# GICSS_GICSS_GIC_01800000h register map
Vendor: Texas Instruments
Peripheral module from a debugger description file (folder am62L).
Registers are 32-bit, access not given, no defined reset value unless marked. A register's access mark holds for its fields unless they carry their own. Offsets are as the file gives them; lines under a group give offsets from that group; [hi:lo] are bit positions; {n}, {i} and the like mark numbered series; 'fields as' and 'values as' point back to an identical list; <NAME> marks a mode.

## GICSS_GIC
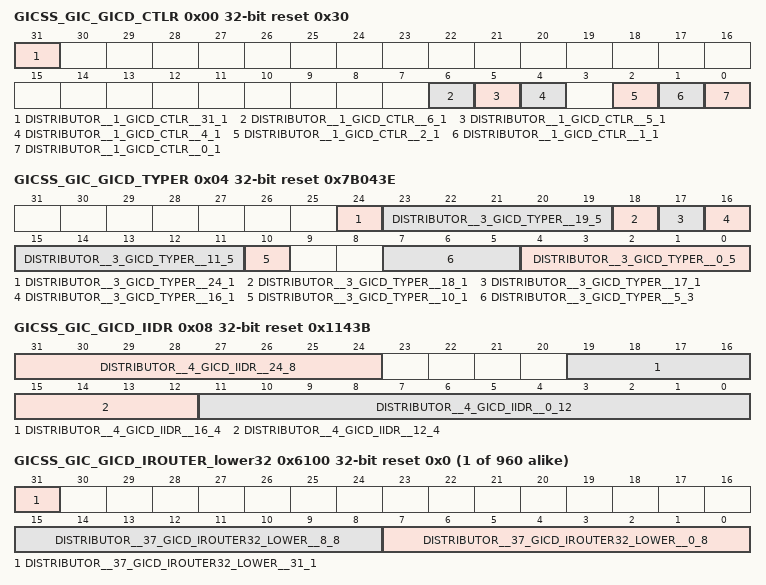
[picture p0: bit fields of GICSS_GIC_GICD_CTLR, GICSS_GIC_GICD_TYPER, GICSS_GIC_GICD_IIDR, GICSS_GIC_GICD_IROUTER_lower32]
0x00 GICSS_GIC_GICD_CTLR rw reset 0x30 — GICD_CTLR
  [31] DISTRIBUTOR__1_GICD_CTLR__31_1 — Register Write Pending
  [6] DISTRIBUTOR__1_GICD_CTLR__6_1 — S: DS
  [5] DISTRIBUTOR__1_GICD_CTLR__5_1 — S: ARE_NS
  [4] DISTRIBUTOR__1_GICD_CTLR__4_1 — NS: ARE_NS S: ARE_S
  [2] DISTRIBUTOR__1_GICD_CTLR__2_1 — S: EnableGrp1_S
  [1] DISTRIBUTOR__1_GICD_CTLR__1_1 — NS: EnableGrp1A S: EnableGrp1_NS
  [0] DISTRIBUTOR__1_GICD_CTLR__0_1 — NS: EnableGrp1 S: EnableGrp0
0x04 GICSS_GIC_GICD_TYPER ro reset 0x7B043E — GICD_TYPER
  [24] DISTRIBUTOR__3_GICD_TYPER__24_1 — A3V
  [23:19] DISTRIBUTOR__3_GICD_TYPER__19_5 — IDbits
  [18] DISTRIBUTOR__3_GICD_TYPER__18_1 — DVIS
  [17] DISTRIBUTOR__3_GICD_TYPER__17_1 — LPIS
  [16] DISTRIBUTOR__3_GICD_TYPER__16_1 — MBIS
  [15:11] DISTRIBUTOR__3_GICD_TYPER__11_5 — LSPI
  [10] DISTRIBUTOR__3_GICD_TYPER__10_1 — SecurityExtn
  [7:5] DISTRIBUTOR__3_GICD_TYPER__5_3 — CPUNumber
  [4:0] DISTRIBUTOR__3_GICD_TYPER__0_5 — ITLinesNumber
0x08 GICSS_GIC_GICD_IIDR ro reset 0x1143B — GICD_IIDR
  [31:24] DISTRIBUTOR__4_GICD_IIDR__24_8 — ProductID
  [19:16] DISTRIBUTOR__4_GICD_IIDR__16_4 — Variant
  [15:12] DISTRIBUTOR__4_GICD_IIDR__12_4 — Revision
  [11:0] DISTRIBUTOR__4_GICD_IIDR__0_12 — Implementer
0x40 GICSS_GIC_GICD_SETSPI_NSR wo reset 0x0 — GICD_SETSPI_NSR
  [9:0] DISTRIBUTOR__5_GICD_SETSPI_NSR__0_10 — SPI ID
0x48 GICSS_GIC_GICD_CLRSPI_NSR wo reset 0x0 — GICD_CLRSPI_NSR
  [9:0] DISTRIBUTOR__6_GICD_CLRSPI_NSR__0_10 — SPI ID
0x50 GICSS_GIC_GICD_SETSPI_SR wo reset 0x0 — GICD_SETSPI_SR
  [9:0] DISTRIBUTOR__7_GICD_SETSPI_SR__0_10 — SPI ID
0x58 GICSS_GIC_GICD_CLRSPI_SR wo reset 0x0 — GICD_CLRSPI_SR
  [9:0] DISTRIBUTOR__8_GICD_CLRSPI_SR__0_10 — SPI ID
0x80 GICSS_GIC_GICD_IGROUPR_SGI_PPI — GICD_IGROUPR0
{0x80+4i} GICSS_GIC_GICD_IGROUPR_SPI{i} (i=1..30) — GICD_IGROUPR{i}
{0x100+4i} GICSS_GIC_GICD_ISENABLER_SPI{i} (i=1..30) — GICD_ISENABLER{i}
{0x180+4i} GICSS_GIC_GICD_ICENABLER_SPI{i} (i=1..30) — GICD_ICENABLER{i}
{0x200+4i} GICSS_GIC_GICD_ISPENDR_SPI{i} (i=1..30) — GICD_ISPENDR{i}
{0x280+4i} GICSS_GIC_GICD_ICPENDR_SPI{i} (i=1..30) — GICD_ICPENDR{i}
{0x300+4i} GICSS_GIC_GICD_ISACTIVER_SPI{i} (i=1..30) — GICD_ISACTIVER{i}
{0x380+4i} GICSS_GIC_GICD_ICACTIVER_SPI{i} (i=1..30) — GICD_ICACTIVER{i}
{0x400+4i} GICSS_GIC_GICD_IPRIORITYR_SPI{i} (i=8..247) — GICD_IPRIORITYR{i}
{0x800+4i} GICSS_GIC_GICD_ITARGETSR_SPI{i} (i=8..247) — GICD_ITARGETSR{i}
{0xC00+4i} GICSS_GIC_GICD_ICFGR_SPI{i} (i=2..61) — GICD_ICFGR{i}
0xD00 GICSS_GIC_GICD_IGRPMODR_SGI_PPI — GICD_IGRPMODR0
{0xD00+4i} GICSS_GIC_GICD_IGRPMODR_SPI{i} (i=1..30) — GICD_IGRPMODR{i}
{0xE00+4i} GICSS_GIC_GICD_NSACR{i} (i=0..61) — GICD_NSACR{i}
{0x6000+8i} GICSS_GIC_GICD_IROUTER_lower{i} rw reset 0x0 (i=32..991) — GICD_IROUTER{i}_lower
  [31] DISTRIBUTOR__37_GICD_IROUTER{i}_LOWER__31_1 — IRM
  [15:8] DISTRIBUTOR__37_GICD_IROUTER{i}_LOWER__8_8 — A1
  [7:0] DISTRIBUTOR__37_GICD_IROUTER{i}_LOWER__0_8 — A0
{0x6004+8i} GICSS_GIC_GICD_IROUTER_upper{i} (i=32..991) — GICD_IROUTER{i}_upper
0xC000 GICSS_GIC_GICD_ESTATUSR ro reset 0x0 — GICD_ESTATUSR
  [31] DISTRIBUTOR__38_GICD_ESTATUSR__31_1 — SWRP
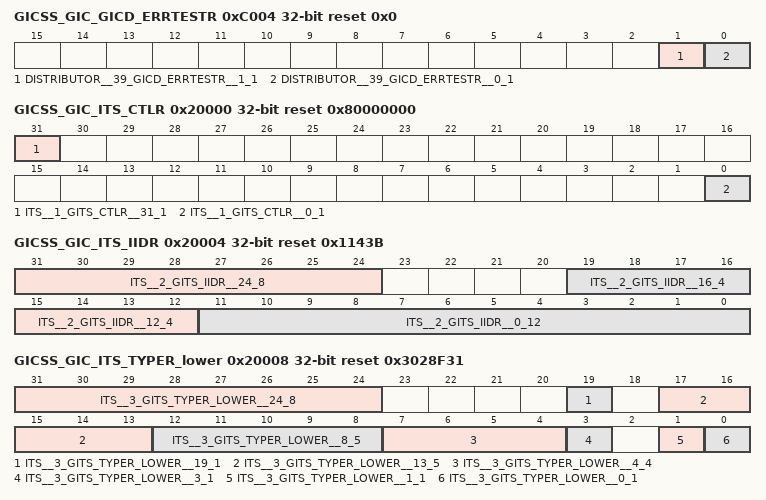
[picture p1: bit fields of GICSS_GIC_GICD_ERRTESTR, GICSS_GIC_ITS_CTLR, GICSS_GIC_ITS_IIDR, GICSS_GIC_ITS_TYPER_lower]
0xC004 GICSS_GIC_GICD_ERRTESTR wo reset 0x0 — GICD_ERRTESTR
  [1] DISTRIBUTOR__39_GICD_ERRTESTR__1_1 — AXIM_err
  [0] DISTRIBUTOR__39_GICD_ERRTESTR__0_1 — ECC_fatal
{0xC084+4i} GICSS_GIC_GICD_SPISR{i} (i=0..29) — GICD_SPISR{i}
{0xFFC0+4i} GICSS_GIC_GICD_PIDR{i} (i=4..7) — GICD_PIDR{i}
{0xFFE0+4i} GICSS_GIC_GICD_PIDR{i} (i=0..3) — GICD_PIDR{i}
{0xFFF0+4i} GICSS_GIC_GICD_CIDR{i} (i=0..3) — GICD_CIDR{i}
0x10040 GICSS_GIC_MSG_SETSPI_NSR wo reset 0x0 — GICD_SETSPI_NSR
  [9:0] MESSAGE_BASED_SPIS__1_GICD_SETSPI_NSR__0_10 — SPI ID
0x10048 GICSS_GIC_MSG_CLRSPI_NSR wo reset 0x0 — GICD_CLRSPI_NSR
  [9:0] MESSAGE_BASED_SPIS__2_GICD_CLRSPI_NSR__0_10 — SPI ID
0x10050 GICSS_GIC_MSG_SETSPI_SR wo reset 0x0 — GICD_SETSPI_SR
  [9:0] MESSAGE_BASED_SPIS__3_GICD_SETSPI_SR__0_10 — SPI ID
0x10058 GICSS_GIC_MSG_CLRSPI_SR wo reset 0x0 — GICD_CLRSPI_SR
  [9:0] MESSAGE_BASED_SPIS__4_GICD_CLRSPI_SR__0_10 — SPI ID
0x20000 GICSS_GIC_ITS_CTLR rw reset 0x80000000 — GITS_CTLR
  [31] ITS__1_GITS_CTLR__31_1 — Quiescent
  [0] ITS__1_GITS_CTLR__0_1 — Enabled
0x20004 GICSS_GIC_ITS_IIDR ro reset 0x1143B — GITS_IIDR
  [31:24] ITS__2_GITS_IIDR__24_8 — ProductID
  [19:16] ITS__2_GITS_IIDR__16_4 — Variant
  [15:12] ITS__2_GITS_IIDR__12_4 — Revision
  [11:0] ITS__2_GITS_IIDR__0_12 — Implementer
0x20008 GICSS_GIC_ITS_TYPER_lower ro reset 0x3028F31 — GITS_TYPER_lower
  [31:24] ITS__3_GITS_TYPER_LOWER__24_8 — HCC
  [19] ITS__3_GITS_TYPER_LOWER__19_1 — PTA
  [17:13] ITS__3_GITS_TYPER_LOWER__13_5 — Devbits
  [12:8] ITS__3_GITS_TYPER_LOWER__8_5 — IDbits
  [7:4] ITS__3_GITS_TYPER_LOWER__4_4 — ITT Entry Size
  [3] ITS__3_GITS_TYPER_LOWER__3_1 — Distributed
  [1] ITS__3_GITS_TYPER_LOWER__1_1 — VLPIS
  [0] ITS__3_GITS_TYPER_LOWER__0_1 — PLPIS
0x2000C GICSS_GIC_ITS_TYPER_upper — GITS_TYPER_upper
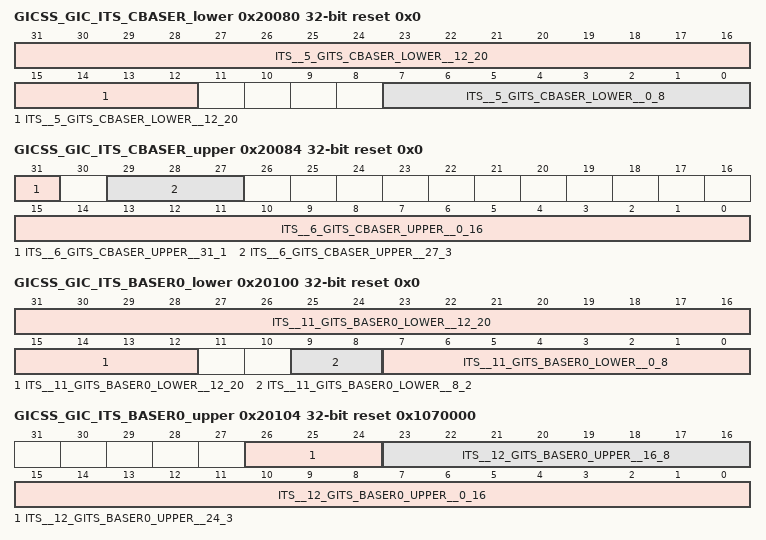
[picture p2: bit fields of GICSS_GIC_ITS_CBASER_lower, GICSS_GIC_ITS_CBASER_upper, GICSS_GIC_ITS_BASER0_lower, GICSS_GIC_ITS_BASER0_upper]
0x20080 GICSS_GIC_ITS_CBASER_lower rw reset 0x0 — GITS_CBASER_lower
  [31:12] ITS__5_GITS_CBASER_LOWER__12_20 — Physical Address [31:12]
  [7:0] ITS__5_GITS_CBASER_LOWER__0_8 — Size
0x20084 GICSS_GIC_ITS_CBASER_upper rw reset 0x0 — GITS_CBASER_upper
  [31] ITS__6_GITS_CBASER_UPPER__31_1 — Valid
  [29:27] ITS__6_GITS_CBASER_UPPER__27_3 — Cacheability
  [15:0] ITS__6_GITS_CBASER_UPPER__0_16 — Physical Address [47:32]
0x20088 GICSS_GIC_ITS_CWRITER_lower rw reset 0x0 — GITS_CWRITER_lower
  [19:5] ITS__7_GITS_CWRITER_LOWER__5_15 — Offset
0x2008C GICSS_GIC_ITS_CWRITER_upper — GITS_CWRITER_upper
0x20090 GICSS_GIC_ITS_CREADR_lower ro reset 0x0 — GITS_CREADR_lower
  [19:5] ITS__9_GITS_CREADR_LOWER__5_15 — Offset
0x20094 GICSS_GIC_ITS_CREADR_upper — GITS_CREADR_upper
0x20100 GICSS_GIC_ITS_BASER0_lower rw reset 0x0 — GITS_BASER0_lower
  [31:12] ITS__11_GITS_BASER0_LOWER__12_20 — Physical Address [31:12]
  [9:8] ITS__11_GITS_BASER0_LOWER__8_2 — Page Size
  [7:0] ITS__11_GITS_BASER0_LOWER__0_8 — Size
0x20104 GICSS_GIC_ITS_BASER0_upper rw reset 0x1070000 — GITS_BASER0_upper
  [26:24] ITS__12_GITS_BASER0_UPPER__24_3 — Type
  [23:16] ITS__12_GITS_BASER0_UPPER__16_8 — Entry Size
  [15:0] ITS__12_GITS_BASER0_UPPER__0_16 — Physical Address [47:32]
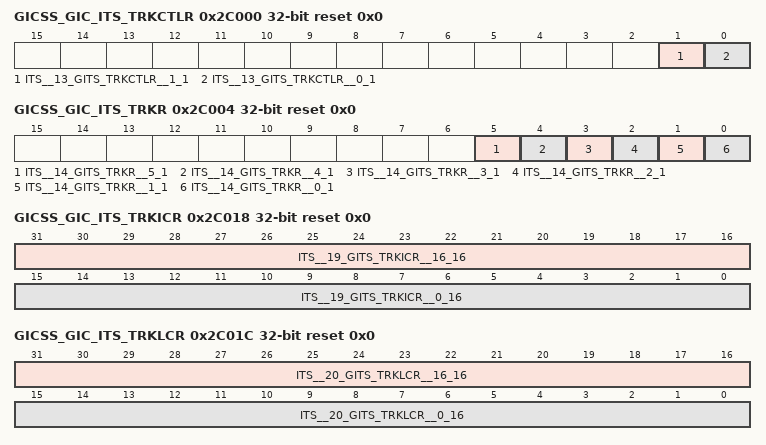
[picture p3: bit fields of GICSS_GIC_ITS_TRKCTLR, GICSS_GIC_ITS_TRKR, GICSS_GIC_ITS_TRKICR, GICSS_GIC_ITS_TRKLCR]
0x2C000 GICSS_GIC_ITS_TRKCTLR wo reset 0x0 — GITS_TRKCTLR
  [1] ITS__13_GITS_TRKCTLR__1_1 — ITS track
  [0] ITS__13_GITS_TRKCTLR__0_1 — Cache count reset
0x2C004 GICSS_GIC_ITS_TRKR ro reset 0x0 — GITS_TRKR
  [5] ITS__14_GITS_TRKR__5_1 — Translated ID out of range
  [4] ITS__14_GITS_TRKR__4_1 — Target CPU out of range
  [3] ITS__14_GITS_TRKR__3_1 — DID/ID not mapped
  [2] ITS__14_GITS_TRKR__2_1 — Input ID out of range
  [1] ITS__14_GITS_TRKR__1_1 — DID unmapped
  [0] ITS__14_GITS_TRKR__0_1 — DID out of range
0x2C008 GICSS_GIC_ITS_TRKDIDR ro reset 0x0 — GITS_TRKDIDR
  [19:0] ITS__15_GITS_TRKDIDR__0_20 — DID
0x2C00C GICSS_GIC_ITS_TRKPIDR ro reset 0x0 — GITS_TRKPIDR
  [15:0] ITS__16_GITS_TRKPIDR__0_16 — Translated ID
0x2C010 GICSS_GIC_ITS_TRKVIDR ro reset 0x0 — GITS_TRKVIDR
  [15:0] ITS__17_GITS_TRKVIDR__0_16 — Input ID
0x2C014 GICSS_GIC_ITS_TRKTGTR ro reset 0x0 — GITS_TRKTGTR
  [6:0] ITS__18_GITS_TRKTGTR__0_7 — Target CPU
0x2C018 GICSS_GIC_ITS_TRKICR ro reset 0x0 — GITS_TRKICR
  [31:16] ITS__19_GITS_TRKICR__16_16 — ITE cache hits
  [15:0] ITS__19_GITS_TRKICR__0_16 — ITE cache misses
0x2C01C GICSS_GIC_ITS_TRKLCR ro reset 0x0 — GITS_TRKLCR
  [31:16] ITS__20_GITS_TRKLCR__16_16 — LPI cache hits
  [15:0] ITS__20_GITS_TRKLCR__0_16 — LPI cache misses
{0x2FFC0+4i} GICSS_GIC_ITS_PIDR{i} (i=4..7) — GITS_PIDR{i}
{0x2FFE0+4i} GICSS_GIC_ITS_PIDR{i} (i=0..3) — GITS_PIDR{i}
{0x2FFF0+4i} GICSS_GIC_ITS_CIDR{i} (i=0..3) — GITS_CIDR{i}
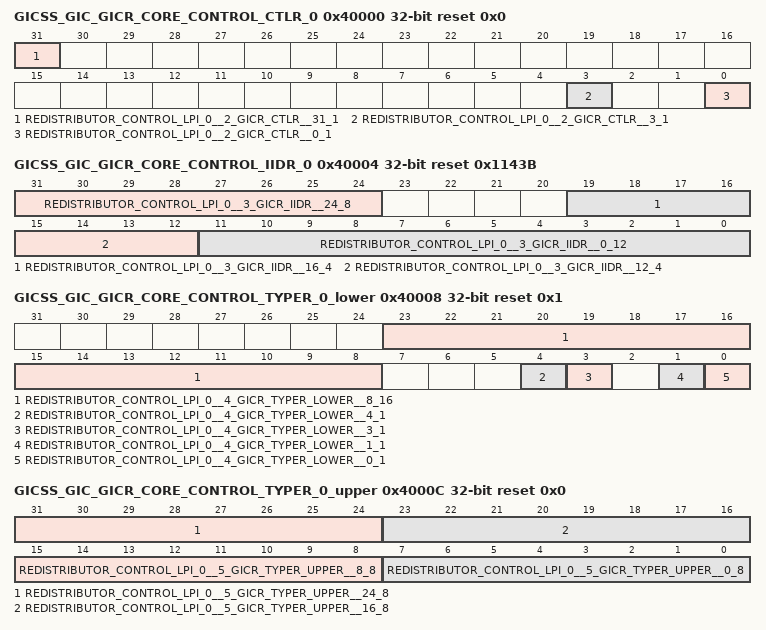
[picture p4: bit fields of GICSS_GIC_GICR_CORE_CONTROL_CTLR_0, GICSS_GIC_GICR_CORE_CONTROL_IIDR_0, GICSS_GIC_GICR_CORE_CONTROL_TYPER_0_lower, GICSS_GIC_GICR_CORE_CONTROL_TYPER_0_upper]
0x40000 GICSS_GIC_GICR_CORE_CONTROL_CTLR_0 rw reset 0x0 — GICR_CTLR
  [31] REDISTRIBUTOR_CONTROL_LPI_0__2_GICR_CTLR__31_1 — Upstream Write Pending
  [3] REDISTRIBUTOR_CONTROL_LPI_0__2_GICR_CTLR__3_1 — Register Write Pending
  [0] REDISTRIBUTOR_CONTROL_LPI_0__2_GICR_CTLR__0_1 — Enable LPIs
0x40004 GICSS_GIC_GICR_CORE_CONTROL_IIDR_0 ro reset 0x1143B — GICR_IIDR
  [31:24] REDISTRIBUTOR_CONTROL_LPI_0__3_GICR_IIDR__24_8 — ProductID
  [19:16] REDISTRIBUTOR_CONTROL_LPI_0__3_GICR_IIDR__16_4 — Variant
  [15:12] REDISTRIBUTOR_CONTROL_LPI_0__3_GICR_IIDR__12_4 — Revision
  [11:0] REDISTRIBUTOR_CONTROL_LPI_0__3_GICR_IIDR__0_12 — Implementer
0x40008 GICSS_GIC_GICR_CORE_CONTROL_TYPER_0_lower ro reset 0x1 — GICR_TYPER_lower
  [23:8] REDISTRIBUTOR_CONTROL_LPI_0__4_GICR_TYPER_LOWER__8_16 — Processor Number
  [4] REDISTRIBUTOR_CONTROL_LPI_0__4_GICR_TYPER_LOWER__4_1 — Last
  [3] REDISTRIBUTOR_CONTROL_LPI_0__4_GICR_TYPER_LOWER__3_1 — Distributed
  [1] REDISTRIBUTOR_CONTROL_LPI_0__4_GICR_TYPER_LOWER__1_1 — VLPIS
  [0] REDISTRIBUTOR_CONTROL_LPI_0__4_GICR_TYPER_LOWER__0_1 — PLPIS
0x4000C GICSS_GIC_GICR_CORE_CONTROL_TYPER_0_upper ro reset 0x0 — GICR_TYPER_upper
  [31:24] REDISTRIBUTOR_CONTROL_LPI_0__5_GICR_TYPER_UPPER__24_8 — A3
  [23:16] REDISTRIBUTOR_CONTROL_LPI_0__5_GICR_TYPER_UPPER__16_8 — A2
  [15:8] REDISTRIBUTOR_CONTROL_LPI_0__5_GICR_TYPER_UPPER__8_8 — A1
  [7:0] REDISTRIBUTOR_CONTROL_LPI_0__5_GICR_TYPER_UPPER__0_8 — A0
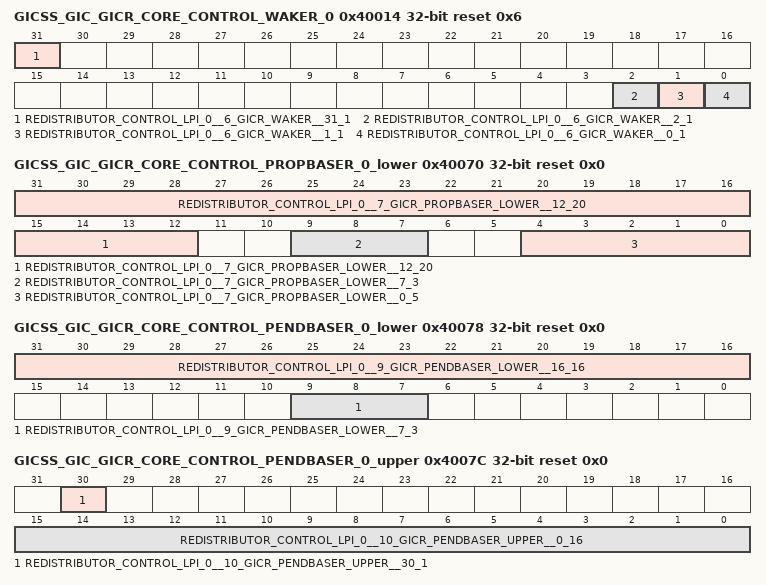
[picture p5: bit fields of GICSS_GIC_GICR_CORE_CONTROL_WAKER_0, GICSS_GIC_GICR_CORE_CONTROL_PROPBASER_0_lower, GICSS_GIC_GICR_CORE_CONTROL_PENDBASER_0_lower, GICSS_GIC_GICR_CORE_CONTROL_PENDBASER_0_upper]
0x40014 GICSS_GIC_GICR_CORE_CONTROL_WAKER_0 rw reset 0x6 — GICR_WAKER
  [31] REDISTRIBUTOR_CONTROL_LPI_0__6_GICR_WAKER__31_1 — Quiescent
  [2] REDISTRIBUTOR_CONTROL_LPI_0__6_GICR_WAKER__2_1 — ChildrenAsleep
  [1] REDISTRIBUTOR_CONTROL_LPI_0__6_GICR_WAKER__1_1 — ProcessorSleep
  [0] REDISTRIBUTOR_CONTROL_LPI_0__6_GICR_WAKER__0_1 — Sleep
0x40070 GICSS_GIC_GICR_CORE_CONTROL_PROPBASER_0_lower rw reset 0x0 — GICR_PROPBASER_lower
  [31:12] REDISTRIBUTOR_CONTROL_LPI_0__7_GICR_PROPBASER_LOWER__12_20 — Physical Address [31:12]
  [9:7] REDISTRIBUTOR_CONTROL_LPI_0__7_GICR_PROPBASER_LOWER__7_3 — Cacheability
  [4:0] REDISTRIBUTOR_CONTROL_LPI_0__7_GICR_PROPBASER_LOWER__0_5 — Idbits
0x40074 GICSS_GIC_GICR_CORE_CONTROL_PROPBASER_0_upper rw reset 0x0 — GICR_PROPBASER_upper
  [15:0] REDISTRIBUTOR_CONTROL_LPI_0__8_GICR_PROPBASER_UPPER__0_16 — Physical Address [47:32]
0x40078 GICSS_GIC_GICR_CORE_CONTROL_PENDBASER_0_lower rw reset 0x0 — GICR_PENDBASER_lower
  [31:16] REDISTRIBUTOR_CONTROL_LPI_0__9_GICR_PENDBASER_LOWER__16_16 — Physical Address [31:16]
  [9:7] REDISTRIBUTOR_CONTROL_LPI_0__9_GICR_PENDBASER_LOWER__7_3 — Cacheability
0x4007C GICSS_GIC_GICR_CORE_CONTROL_PENDBASER_0_upper rw reset 0x0 — GICR_PENDBASER_upper
  [30] REDISTRIBUTOR_CONTROL_LPI_0__10_GICR_PENDBASER_UPPER__30_1 — Pending Table Zero
  [15:0] REDISTRIBUTOR_CONTROL_LPI_0__10_GICR_PENDBASER_UPPER__0_16 — Physical Address [47:32]
{0x4FFC0+4i} GICSS_GIC_GICR_CORE_CONTROL_PIDR{i}_0 (i=4..7) — GICR_PIDR{i}
{0x4FFE0+4i} GICSS_GIC_GICR_CORE_CONTROL_PIDR{i}_0 (i=0..3) — GICR_PIDR{i}
{0x4FFF0+4i} GICSS_GIC_GICR_CORE_CONTROL_CIDR{i}_0 (i=0..3) — GICR_CIDR{i}
0x50080 GICSS_GIC_GICR_CORE_SGI_PPI_IGROUPR_SGI_PPI0 — GICR_IGROUPR0
0x50100 GICSS_GIC_GICR_CORE_SGI_PPI_ISENABLER00 — GICR_ISENABLER0
0x50180 GICSS_GIC_GICR_CORE_SGI_PPI_ICENABLER00 — GICR_ICENABLER0
0x50200 GICSS_GIC_GICR_CORE_SGI_PPI_ISPENDR00 — GICR_ISPENDR0
0x50280 GICSS_GIC_GICR_CORE_SGI_PPI_ICPENDR00 — GICR_ICPENDR0
0x50300 GICSS_GIC_GICR_CORE_SGI_PPI_ISACTIVER00 — GICR_ISACTIVER0
0x50380 GICSS_GIC_GICR_CORE_SGI_PPI_ICACTIVER00 — GICR_ICACTIVER0
0x50400 GICSS_GIC_GICR_CORE_SGI_PPI_IPRIORITYR00 — GICR_IPRIORITYR0
0x50404 GICSS_GIC_GICR_CORE_SGI_PPI_IPRIORITYR10 — GICR_IPRIORITYR1
0x50408 GICSS_GIC_GICR_CORE_SGI_PPI_IPRIORITYR20 — GICR_IPRIORITYR2
0x5040C GICSS_GIC_GICR_CORE_SGI_PPI_IPRIORITYR30 — GICR_IPRIORITYR3
0x50410 GICSS_GIC_GICR_CORE_SGI_PPI_IPRIORITYR40 — GICR_IPRIORITYR4
0x50414 GICSS_GIC_GICR_CORE_SGI_PPI_IPRIORITYR50 — GICR_IPRIORITYR5
0x50418 GICSS_GIC_GICR_CORE_SGI_PPI_IPRIORITYR60 — GICR_IPRIORITYR6
0x5041C GICSS_GIC_GICR_CORE_SGI_PPI_IPRIORITYR70 — GICR_IPRIORITYR7
0x50C00 GICSS_GIC_GICR_CORE_SGI_PPI_ICFGR00 — GICR_ICFGR0
0x50C04 GICSS_GIC_GICR_CORE_SGI_PPI_ICFGR10 — GICR_ICFGR1
0x50D00 GICSS_GIC_GICR_CORE_SGI_PPI_IGRPMODR_SGI_PPI0 — GICR_IGRPMODR0
0x50E00 GICSS_GIC_GICR_CORE_SGI_PPI_NSACR0 — GICR_NSACR
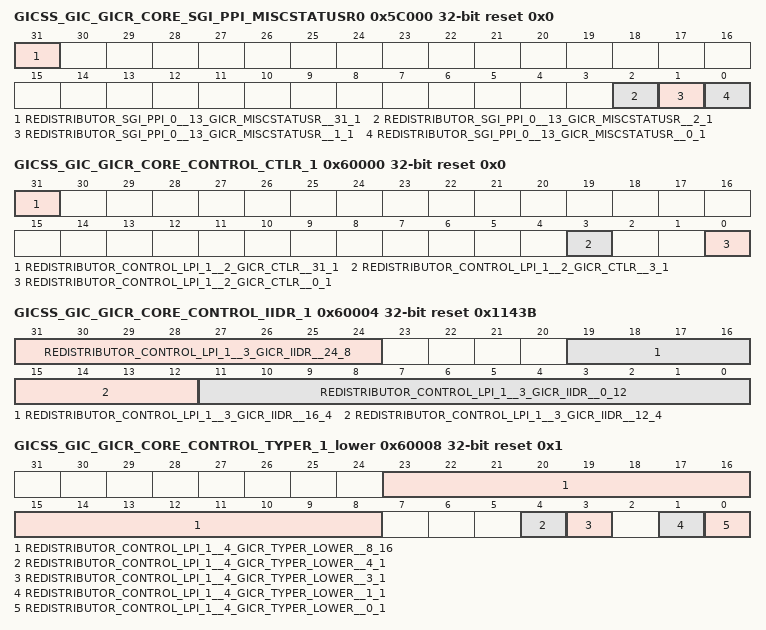
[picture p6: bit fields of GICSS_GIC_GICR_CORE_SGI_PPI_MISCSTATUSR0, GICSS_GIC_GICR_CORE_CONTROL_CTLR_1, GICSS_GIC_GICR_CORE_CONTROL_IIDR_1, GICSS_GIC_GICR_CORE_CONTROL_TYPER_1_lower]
0x5C000 GICSS_GIC_GICR_CORE_SGI_PPI_MISCSTATUSR0 ro reset 0x0 — GICR_MISCSTATUSR
  [31] REDISTRIBUTOR_SGI_PPI_0__13_GICR_MISCSTATUSR__31_1 — cpu_active
  [2] REDISTRIBUTOR_SGI_PPI_0__13_GICR_MISCSTATUSR__2_1 — EnableGrp1_S
  [1] REDISTRIBUTOR_SGI_PPI_0__13_GICR_MISCSTATUSR__1_1 — EnableGrp1_NS
  [0] REDISTRIBUTOR_SGI_PPI_0__13_GICR_MISCSTATUSR__0_1 — EnableGrp0
0x5C080 GICSS_GIC_GICR_CORE_SGI_PPI_PPISR0 ro reset 0x0 — GICR_PPISR
  [31:16] REDISTRIBUTOR_SGI_PPI_0__14_GICR_PPISR__16_16 — PPI status
0x60000 GICSS_GIC_GICR_CORE_CONTROL_CTLR_1 rw reset 0x0 — GICR_CTLR
  [31] REDISTRIBUTOR_CONTROL_LPI_1__2_GICR_CTLR__31_1 — Upstream Write Pending
  [3] REDISTRIBUTOR_CONTROL_LPI_1__2_GICR_CTLR__3_1 — Register Write Pending
  [0] REDISTRIBUTOR_CONTROL_LPI_1__2_GICR_CTLR__0_1 — Enable LPIs
0x60004 GICSS_GIC_GICR_CORE_CONTROL_IIDR_1 ro reset 0x1143B — GICR_IIDR
  [31:24] REDISTRIBUTOR_CONTROL_LPI_1__3_GICR_IIDR__24_8 — ProductID
  [19:16] REDISTRIBUTOR_CONTROL_LPI_1__3_GICR_IIDR__16_4 — Variant
  [15:12] REDISTRIBUTOR_CONTROL_LPI_1__3_GICR_IIDR__12_4 — Revision
  [11:0] REDISTRIBUTOR_CONTROL_LPI_1__3_GICR_IIDR__0_12 — Implementer
0x60008 GICSS_GIC_GICR_CORE_CONTROL_TYPER_1_lower ro reset 0x1 — GICR_TYPER_lower
  [23:8] REDISTRIBUTOR_CONTROL_LPI_1__4_GICR_TYPER_LOWER__8_16 — Processor Number
  [4] REDISTRIBUTOR_CONTROL_LPI_1__4_GICR_TYPER_LOWER__4_1 — Last
  [3] REDISTRIBUTOR_CONTROL_LPI_1__4_GICR_TYPER_LOWER__3_1 — Distributed
  [1] REDISTRIBUTOR_CONTROL_LPI_1__4_GICR_TYPER_LOWER__1_1 — VLPIS
  [0] REDISTRIBUTOR_CONTROL_LPI_1__4_GICR_TYPER_LOWER__0_1 — PLPIS
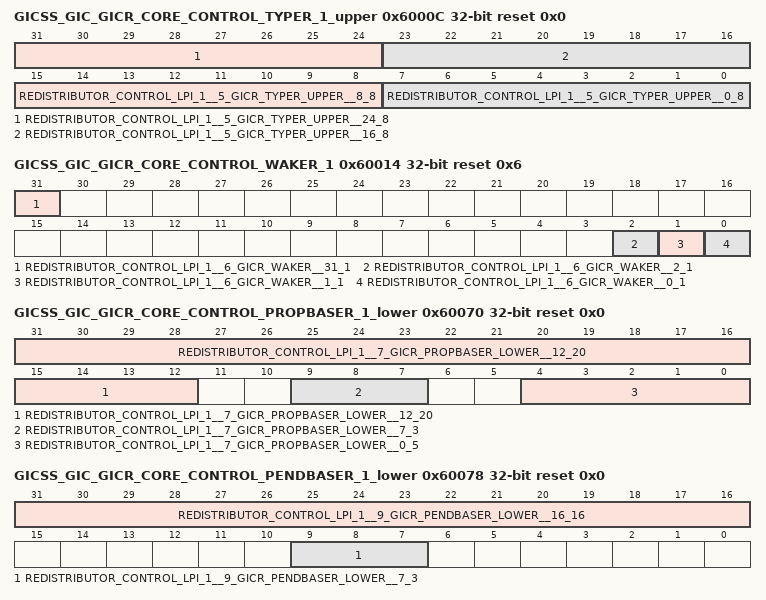
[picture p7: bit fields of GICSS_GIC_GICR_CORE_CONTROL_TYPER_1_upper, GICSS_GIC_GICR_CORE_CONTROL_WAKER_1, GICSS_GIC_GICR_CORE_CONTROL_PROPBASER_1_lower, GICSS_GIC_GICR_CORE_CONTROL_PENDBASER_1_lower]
0x6000C GICSS_GIC_GICR_CORE_CONTROL_TYPER_1_upper ro reset 0x0 — GICR_TYPER_upper
  [31:24] REDISTRIBUTOR_CONTROL_LPI_1__5_GICR_TYPER_UPPER__24_8 — A3
  [23:16] REDISTRIBUTOR_CONTROL_LPI_1__5_GICR_TYPER_UPPER__16_8 — A2
  [15:8] REDISTRIBUTOR_CONTROL_LPI_1__5_GICR_TYPER_UPPER__8_8 — A1
  [7:0] REDISTRIBUTOR_CONTROL_LPI_1__5_GICR_TYPER_UPPER__0_8 — A0
0x60014 GICSS_GIC_GICR_CORE_CONTROL_WAKER_1 rw reset 0x6 — GICR_WAKER
  [31] REDISTRIBUTOR_CONTROL_LPI_1__6_GICR_WAKER__31_1 — Quiescent
  [2] REDISTRIBUTOR_CONTROL_LPI_1__6_GICR_WAKER__2_1 — ChildrenAsleep
  [1] REDISTRIBUTOR_CONTROL_LPI_1__6_GICR_WAKER__1_1 — ProcessorSleep
  [0] REDISTRIBUTOR_CONTROL_LPI_1__6_GICR_WAKER__0_1 — Sleep
0x60070 GICSS_GIC_GICR_CORE_CONTROL_PROPBASER_1_lower rw reset 0x0 — GICR_PROPBASER_lower
  [31:12] REDISTRIBUTOR_CONTROL_LPI_1__7_GICR_PROPBASER_LOWER__12_20 — Physical Address [31:12]
  [9:7] REDISTRIBUTOR_CONTROL_LPI_1__7_GICR_PROPBASER_LOWER__7_3 — Cacheability
  [4:0] REDISTRIBUTOR_CONTROL_LPI_1__7_GICR_PROPBASER_LOWER__0_5 — Idbits
0x60074 GICSS_GIC_GICR_CORE_CONTROL_PROPBASER_1_upper rw reset 0x0 — GICR_PROPBASER_upper
  [15:0] REDISTRIBUTOR_CONTROL_LPI_1__8_GICR_PROPBASER_UPPER__0_16 — Physical Address [47:32]
0x60078 GICSS_GIC_GICR_CORE_CONTROL_PENDBASER_1_lower rw reset 0x0 — GICR_PENDBASER_lower
  [31:16] REDISTRIBUTOR_CONTROL_LPI_1__9_GICR_PENDBASER_LOWER__16_16 — Physical Address [31:16]
  [9:7] REDISTRIBUTOR_CONTROL_LPI_1__9_GICR_PENDBASER_LOWER__7_3 — Cacheability
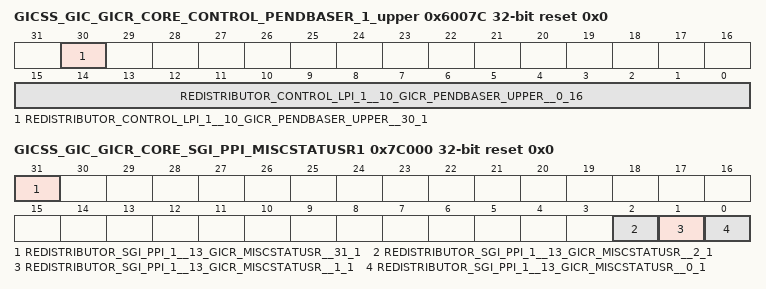
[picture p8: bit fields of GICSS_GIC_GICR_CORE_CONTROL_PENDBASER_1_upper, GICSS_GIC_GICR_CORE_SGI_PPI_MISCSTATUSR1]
0x6007C GICSS_GIC_GICR_CORE_CONTROL_PENDBASER_1_upper rw reset 0x0 — GICR_PENDBASER_upper
  [30] REDISTRIBUTOR_CONTROL_LPI_1__10_GICR_PENDBASER_UPPER__30_1 — Pending Table Zero
  [15:0] REDISTRIBUTOR_CONTROL_LPI_1__10_GICR_PENDBASER_UPPER__0_16 — Physical Address [47:32]
{0x6FFC0+4i} GICSS_GIC_GICR_CORE_CONTROL_PIDR{i}_1 (i=4..7) — GICR_PIDR{i}
{0x6FFE0+4i} GICSS_GIC_GICR_CORE_CONTROL_PIDR{i}_1 (i=0..3) — GICR_PIDR{i}
{0x6FFF0+4i} GICSS_GIC_GICR_CORE_CONTROL_CIDR{i}_1 (i=0..3) — GICR_CIDR{i}
0x70080 GICSS_GIC_GICR_CORE_SGI_PPI_IGROUPR_SGI_PPI0 — GICR_IGROUPR0
0x70100 GICSS_GIC_GICR_CORE_SGI_PPI_ISENABLER01 — GICR_ISENABLER0
0x70180 GICSS_GIC_GICR_CORE_SGI_PPI_ICENABLER01 — GICR_ICENABLER0
0x70200 GICSS_GIC_GICR_CORE_SGI_PPI_ISPENDR01 — GICR_ISPENDR0
0x70280 GICSS_GIC_GICR_CORE_SGI_PPI_ICPENDR01 — GICR_ICPENDR0
0x70300 GICSS_GIC_GICR_CORE_SGI_PPI_ISACTIVER01 — GICR_ISACTIVER0
0x70380 GICSS_GIC_GICR_CORE_SGI_PPI_ICACTIVER01 — GICR_ICACTIVER0
0x70400 GICSS_GIC_GICR_CORE_SGI_PPI_IPRIORITYR01 — GICR_IPRIORITYR0
0x70404 GICSS_GIC_GICR_CORE_SGI_PPI_IPRIORITYR11 — GICR_IPRIORITYR1
0x70408 GICSS_GIC_GICR_CORE_SGI_PPI_IPRIORITYR21 — GICR_IPRIORITYR2
0x7040C GICSS_GIC_GICR_CORE_SGI_PPI_IPRIORITYR31 — GICR_IPRIORITYR3
0x70410 GICSS_GIC_GICR_CORE_SGI_PPI_IPRIORITYR41 — GICR_IPRIORITYR4
0x70414 GICSS_GIC_GICR_CORE_SGI_PPI_IPRIORITYR51 — GICR_IPRIORITYR5
0x70418 GICSS_GIC_GICR_CORE_SGI_PPI_IPRIORITYR61 — GICR_IPRIORITYR6
0x7041C GICSS_GIC_GICR_CORE_SGI_PPI_IPRIORITYR71 — GICR_IPRIORITYR7
0x70C00 GICSS_GIC_GICR_CORE_SGI_PPI_ICFGR01 — GICR_ICFGR0
0x70C04 GICSS_GIC_GICR_CORE_SGI_PPI_ICFGR11 — GICR_ICFGR1
0x70D00 GICSS_GIC_GICR_CORE_SGI_PPI_IGRPMODR_SGI_PPI0 — GICR_IGRPMODR0
0x70E00 GICSS_GIC_GICR_CORE_SGI_PPI_NSACR1 — GICR_NSACR
0x7C000 GICSS_GIC_GICR_CORE_SGI_PPI_MISCSTATUSR1 ro reset 0x0 — GICR_MISCSTATUSR
  [31] REDISTRIBUTOR_SGI_PPI_1__13_GICR_MISCSTATUSR__31_1 — cpu_active
  [2] REDISTRIBUTOR_SGI_PPI_1__13_GICR_MISCSTATUSR__2_1 — EnableGrp1_S
  [1] REDISTRIBUTOR_SGI_PPI_1__13_GICR_MISCSTATUSR__1_1 — EnableGrp1_NS
  [0] REDISTRIBUTOR_SGI_PPI_1__13_GICR_MISCSTATUSR__0_1 — EnableGrp0
0x7C080 GICSS_GIC_GICR_CORE_SGI_PPI_PPISR1 ro reset 0x0 — GICR_PPISR
  [31:16] REDISTRIBUTOR_SGI_PPI_1__14_GICR_PPISR__16_16 — PPI status
